# STM32GBK1CBT6 register map
File version: 1.2
CPU: CM4 r0p1, little endian, MPU, FPU, 4 interrupt priority bits
Registers are 32-bit, read-write, reset 0x0 unless marked. A register's access mark holds for its fields unless they carry their own. Offsets are from the block's base; [hi:lo] are bit positions; {n}, {i} and the like mark numbered series.

## TIM15 — General purpose timers
Base 0x40014000
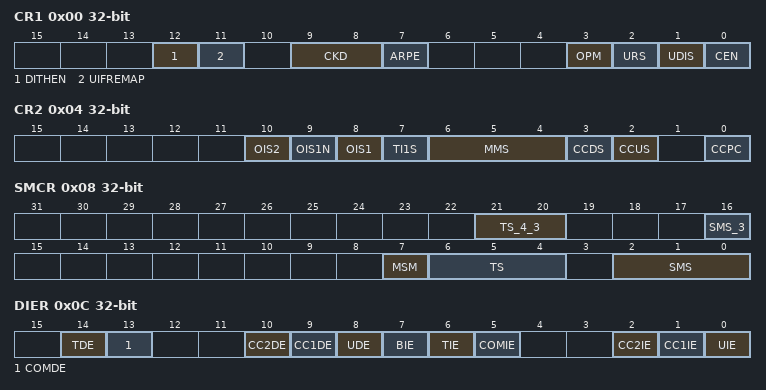
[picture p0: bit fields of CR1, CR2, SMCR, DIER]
0x00 CR1 — control register 1
  [12] DITHEN — Dithering Enable
  [11] UIFREMAP — UIF status bit remapping
  [9:8] CKD — Clock division
  [7] ARPE — Auto-reload preload enable
  [3] OPM — One-pulse mode
  [2] URS — Update request source
  [1] UDIS — Update disable
  [0] CEN — Counter enable
0x04 CR2 — control register 2
  [10] OIS2 — Output idle state 2 (OC2 output)
  [9] OIS1N — Output Idle state 1
  [8] OIS1 — Output Idle state 1
  [7] TI1S — TI1 selection
  [6:4] MMS — Master mode selection
  [3] CCDS — Capture/compare DMA selection
  [2] CCUS — Capture/compare control update selection
  [0] CCPC — Capture/compare preloaded control
0x08 SMCR — slave mode control register
  [21:20] TS_4_3 — Trigger selection - bit 4:3
  [16] SMS_3 — Slave mode selection - bit 3
  [7] MSM — Master/Slave mode
  [6:4] TS — Trigger selection
  [2:0] SMS — Slave mode selection
0x0C DIER — DMA/Interrupt enable register
  [14] TDE — Trigger DMA request enable
  [13] COMDE — COM DMA request enable
  [10] CC2DE — Capture/Compare 2 DMA request enable
  [9] CC1DE — Capture/Compare 1 DMA request enable
  [8] UDE — Update DMA request enable
  [7] BIE — Break interrupt enable
  [6] TIE — Trigger interrupt enable
  [5] COMIE — COM interrupt enable
  [2] CC2IE — Capture/Compare 2 interrupt enable
  [1] CC1IE — Capture/Compare 1 interrupt enable
  [0] UIE — Update interrupt enable
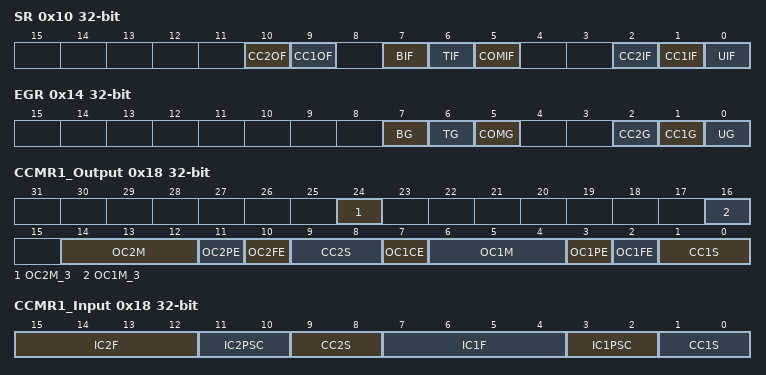
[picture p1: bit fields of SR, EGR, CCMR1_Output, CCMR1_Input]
0x10 SR — status register
  [10] CC2OF — Capture/Compare 2 overcapture flag
  [9] CC1OF — Capture/Compare 1 overcapture flag
  [7] BIF — Break interrupt flag
  [6] TIF — Trigger interrupt flag
  [5] COMIF — COM interrupt flag
  [2] CC2IF — Capture/compare 2 interrupt flag
  [1] CC1IF — Capture/compare 1 interrupt flag
  [0] UIF — Update interrupt flag
0x14 EGR wo — event generation register
  [7] BG — Break generation
  [6] TG — Trigger generation
  [5] COMG — Capture/Compare control update generation
  [2] CC2G — Capture/compare 2 generation
  [1] CC1G — Capture/compare 1 generation
  [0] UG — Update generation
0x18 CCMR1_Output — capture/compare mode register (output mode)
  [24] OC2M_3 — Output Compare 2 mode - bit 3
  [16] OC1M_3 — Output Compare 1 mode
  [14:12] OC2M
  [11] OC2PE
  [10] OC2FE
  [9:8] CC2S
  [7] OC1CE
  [6:4] OC1M — Output Compare 1 mode
  [3] OC1PE — Output Compare 1 preload enable
  [2] OC1FE — Output Compare 1 fast enable
  [1:0] CC1S — Capture/Compare 1 selection
0x18 CCMR1_Input (alternate view of CCMR1_Output) — capture/compare mode register 1 (input mode)
  [15:12] IC2F
  [11:10] IC2PSC
  [9:8] CC2S
  [7:4] IC1F — Input capture 1 filter
  [3:2] IC1PSC — Input capture 1 prescaler
  [1:0] CC1S — Capture/Compare 1 selection
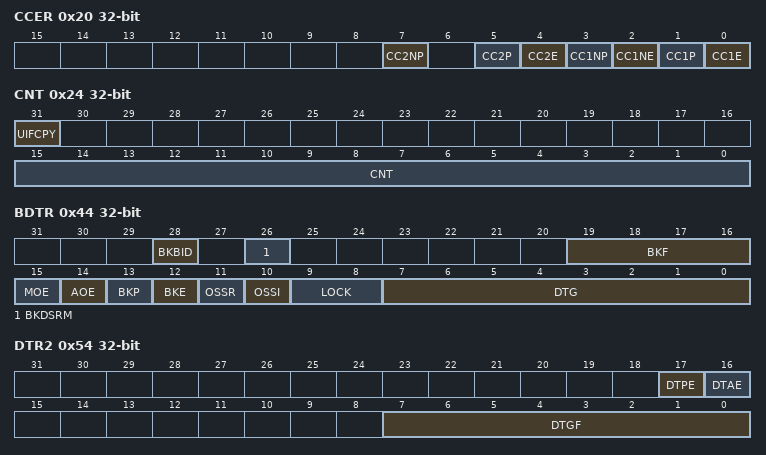
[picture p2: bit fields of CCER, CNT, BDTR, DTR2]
0x20 CCER — capture/compare enable register
  [7] CC2NP — Capture/Compare 2 complementary output polarity
  [5] CC2P — Capture/Compare 2 output polarity
  [4] CC2E — Capture/Compare 2 output enable
  [3] CC1NP — Capture/Compare 1 output Polarity
  [2] CC1NE — Capture/Compare 1 complementary output enable
  [1] CC1P — Capture/Compare 1 output Polarity
  [0] CC1E — Capture/Compare 1 output enable
0x24 CNT access per field — counter
  [31] UIFCPY ro — UIF Copy
  [15:0] CNT rw — counter value
0x28 PSC — prescaler
  [15:0] PSC — Prescaler value
0x2C ARR reset 0xFFFF — auto-reload register
  [15:0] ARR — Auto-reload value
0x30 RCR — repetition counter register
  [7:0] REP — Repetition counter value
0x34 CCR1 — capture/compare register 1
  [15:0] CCR1 — Capture/Compare 1 value
0x38 CCR2 — capture/compare register 2
  [15:0] CCR2 — Capture/Compare 1 value
0x44 BDTR — break and dead-time register
  [28] BKBID
  [26] BKDSRM
  [19:16] BKF — Break filter
  [15] MOE — Main output enable
  [14] AOE — Automatic output enable
  [13] BKP — Break polarity
  [12] BKE — Break enable
  [11] OSSR — Off-state selection for Run mode
  [10] OSSI — Off-state selection for Idle mode
  [9:8] LOCK — Lock configuration
  [7:0] DTG — Dead-time generator setup
0x54 DTR2 — timer Deadtime Register 2
  [17] DTPE — Deadtime Preload Enable
  [16] DTAE — Deadtime Asymmetric Enable
  [7:0] DTGF — Dead-time generator setup
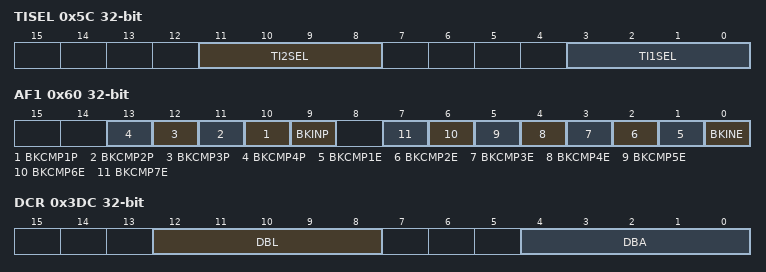
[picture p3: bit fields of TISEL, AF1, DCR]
0x5C TISEL — TIM timer input selection register
  [11:8] TI2SEL — TI2[0] to TI2[15] input selection
  [3:0] TI1SEL — TI1[0] to TI1[15] input selection
0x60 AF1 — TIM alternate function option register 1
  [n+9] BKCMP{n}P (n=1..4) — BRK COMP{n} input polarity
  [9] BKINP — BRK BKIN input polarity
  [n] BKCMP{n}E (n=1..7) — BRK COMP{n} enable
  [0] BKINE — BRK BKIN input enable
0x64 AF2 — TIM alternate function option register 2
  [18:16] OCRSEL — OCREF_CLR source selection
0x3DC DCR — DMA control register
  [12:8] DBL — DMA burst length
  [4:0] DBA — DMA base address
0x3E0 DMAR — DMA address for full transfer
  [31:0] DMAB — DMA register for burst accesses
